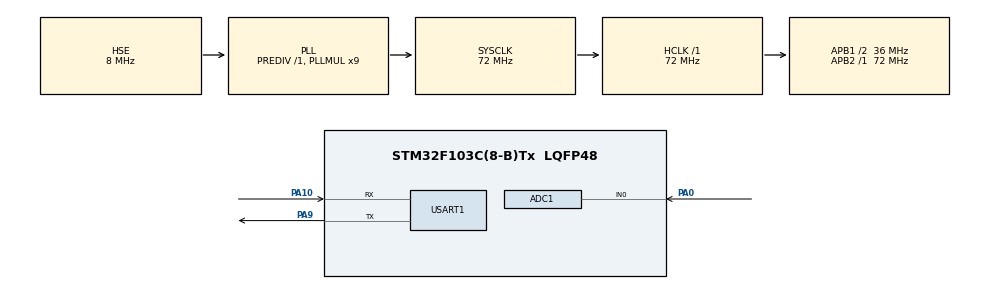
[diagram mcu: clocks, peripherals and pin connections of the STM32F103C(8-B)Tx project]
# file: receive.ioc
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ADC1.Channel-0\#ChannelRegularConversion=ADC_CHANNEL_0
ADC1.NbrOfConversionFlag=1
ADC1.Rank-0\#ChannelRegularConversion=1
ADC1.SamplingTime-0\#ChannelRegularConversion=ADC_SAMPLETIME_1CYCLE_5
ADC1.master=1
Dma.Request0=USART1_TX
Dma.Request1=USART1_RX
Dma.USART1_RX.1.Direction=DMA_PERIPH_TO_MEMORY
Dma.USART1_RX.1.Instance=DMA1_Channel5
Dma.USART1_RX.1.MemDataAlignment=DMA_MDATAALIGN_BYTE
Dma.USART1_RX.1.MemInc=DMA_MINC_ENABLE
Dma.USART1_RX.1.Mode=DMA_NORMAL
Dma.USART1_RX.1.PeriphDataAlignment=DMA_PDATAALIGN_BYTE
Dma.USART1_RX.1.PeriphInc=DMA_PINC_DISABLE
Dma.USART1_RX.1.Priority=DMA_PRIORITY_LOW
Dma.USART1_TX.0.Direction=DMA_MEMORY_TO_PERIPH
Dma.USART1_TX.0.Instance=DMA1_Channel4
Dma.USART1_TX.0.MemDataAlignment=DMA_MDATAALIGN_BYTE
Dma.USART1_TX.0.MemInc=DMA_MINC_ENABLE
Dma.USART1_TX.0.Mode=DMA_NORMAL
Dma.USART1_TX.0.PeriphDataAlignment=DMA_PDATAALIGN_BYTE
Dma.USART1_TX.0.PeriphInc=DMA_PINC_DISABLE
Dma.USART1_TX.0.Priority=DMA_PRIORITY_LOW
Mcu.Family=STM32F1
Mcu.Name=STM32F103C(8-B)Tx
Mcu.Package=LQFP48
NVIC.DMA1_Channel4_IRQn=true\:0\:0\:false\:false\:true\:false\:true\:true
NVIC.DMA1_Channel5_IRQn=true\:0\:0\:false\:false\:true\:false\:true\:true
NVIC.PriorityGroup=NVIC_PRIORITYGROUP_4
NVIC.USART1_IRQn=true\:0\:0\:false\:false\:true\:false\:true\:true
PA0-WKUP.Signal=ADCx_IN0
PA10.Mode=Asynchronous
PA10.Signal=USART1_RX
PA13.Mode=Serial_Wire
PA13.Signal=SYS_JTMS-SWDIO
PA14.Mode=Serial_Wire
PA14.Signal=SYS_JTCK-SWCLK
PA9.Mode=Asynchronous
PA9.Signal=USART1_TX
PD0-OSC_IN.Mode=HSE-External-Oscillator
PD0-OSC_IN.Signal=RCC_OSC_IN
PD1-OSC_OUT.Mode=HSE-External-Oscillator
PD1-OSC_OUT.Signal=RCC_OSC_OUT
ProjectManager.HeapSize=0x200
ProjectManager.StackSize=0x400
ProjectManager.TargetToolchain=CMake
RCC.ADCPresc=RCC_ADCPCLK2_DIV6
RCC.AHBFreq_Value=72000000
RCC.APB1CLKDivider=RCC_HCLK_DIV2
RCC.APB1Freq_Value=36000000
RCC.APB1TimFreq_Value=72000000
RCC.APB2Freq_Value=72000000
RCC.APB2TimFreq_Value=72000000
RCC.HCLKFreq_Value=72000000
RCC.PLLMUL=RCC_PLL_MUL9
RCC.PLLSourceVirtual=RCC_PLLSOURCE_HSE
RCC.SYSCLKFreq_VALUE=72000000
RCC.SYSCLKSource=RCC_SYSCLKSOURCE_PLLCLK
RCC.USBFreq_Value=72000000
SH.ADCx_IN0.0=ADC1_IN0,IN0
USART1.VirtualMode=VM_ASYNC
board=custom

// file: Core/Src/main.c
/* USER CODE BEGIN Header */
/**
  ******************************************************************************
  * @file           : main.c
  * @brief          : Main program body
  ******************************************************************************
  * @attention
  *
  * Copyright (c) 2026 STMicroelectronics.
  * All rights reserved.
  *
  * This software is licensed under terms that can be found in the LICENSE file
  * in the root directory of this software component.
  * If no LICENSE file comes with this software, it is provided AS-IS.
  *
  ******************************************************************************
  */
/* USER CODE END Header */
#include "main.h"

/* USER CODE BEGIN Includes */
#include <string.h>
/* USER CODE END Includes */

/* USER CODE BEGIN PD */
#define RX_BUF_SIZE   64U   /* DMA 接收缓冲区大小，一帧最长 64 字节 */
/* USER CODE END PD */

ADC_HandleTypeDef hadc1;

UART_HandleTypeDef huart1;
DMA_HandleTypeDef hdma_usart1_tx;
DMA_HandleTypeDef hdma_usart1_rx;

/* USER CODE BEGIN PV */
uint8_t           rx_buf[RX_BUF_SIZE];      /* DMA 直接写入的缓冲区 */
uint8_t           frame_buf[RX_BUF_SIZE];   /* 拷贝出来给主循环用，长度=实际收到字节数 */
volatile uint16_t frame_len   = 0U;         /* 本帧实际长度 */
volatile uint8_t  frame_ready = 0U;         /* 1 = 收到完整一帧，待主循环处理 */
/* USER CODE END PV */

void SystemClock_Config(void);
static void MX_GPIO_Init(void);
static void MX_DMA_Init(void);
static void MX_ADC1_Init(void);
static void MX_USART1_UART_Init(void);
/* USER CODE BEGIN PFP */
static void uart_send_str(const char *s);
static void uart_send_u16(uint16_t v);
static void uart_start_rx(void);
/* USER CODE END PFP */

/* USER CODE BEGIN 0 */
/* 发送一个以 '\0' 结尾的字符串 */
static void uart_send_str(const char *s)
{
  HAL_UART_Transmit(&huart1, (uint8_t *)s, (uint16_t)strlen(s), 100U);
}

/* 发送一个无符号整数（避免引入 printf，省 flash） */
static void uart_send_u16(uint16_t v)
{
  char    buf[6];
  uint8_t n = 0U;
  uint8_t i;
  char    t;

  if (v == 0U)
  {
    buf[n++] = '0';
  }
  else
  {
    while ((v > 0U) && (n < sizeof(buf)))
    {
      buf[n++] = (char)('0' + (v % 10U));
      v /= 10U;
    }
    for (i = 0U; i < (n / 2U); i++)      /* 上面是逆序，翻转回来 */
    {
      t = buf[i];
      buf[i] = buf[n - 1U - i];
      buf[n - 1U - i] = t;
    }
  }
  HAL_UART_Transmit(&huart1, (uint8_t *)buf, n, 100U);
}

/* 启动一次"不定长"接收：DMA 搬运 + 串口空闲中断判帧尾 */
static void uart_start_rx(void)
{
  HAL_UARTEx_ReceiveToIdle_DMA(&huart1, rx_buf, RX_BUF_SIZE);

  /* ReceiveToIdle_DMA 每次都会把 DMA 半传输中断也打开，
     缓冲区一半时会误触发一次回调。这里关掉，只要空闲事件。 */
  __HAL_DMA_DISABLE_IT(&hdma_usart1_rx, DMA_IT_HT);
}
/* USER CODE END 0 */

int main(void)
{

  /* MCU Configuration--------------------------------------------------------*/

  /* Reset of all peripherals, Initializes the Flash interface and the Systick. */
  HAL_Init();

  /* Configure the system clock */
  SystemClock_Config();

  /* Initialize all configured peripherals */
  MX_GPIO_Init();
  MX_DMA_Init();
  MX_ADC1_Init();
  MX_USART1_UART_Init();
  /* USER CODE BEGIN 2 */
  uart_send_str("\r\n===== 不定长数据接收（DMA + 空闲中断）=====\r\n");
  uart_send_str("发送任意长度内容，接收方会回显长度和原文\r\n");
  uart_send_str("缓冲区 ");
  uart_send_u16(RX_BUF_SIZE);
  uart_send_str(" 字节，超长会自动分帧\r\n");

  uart_start_rx();   /* 挂上第一次接收 */
  /* USER CODE END 2 */

  /* Infinite loop */
  while (1)
  {

    /* USER CODE BEGIN 3 */
    if (frame_ready != 0U)
    {
      uint16_t len;

      frame_ready = 0U;      /* 先清标志，再处理数据 */
      len = frame_len;

      /* 回显：长度 + 原文（发送长度本身就是"不定长发送"） */
      uart_send_str("\r\n[收到 ");
      uart_send_u16(len);
      uart_send_str(" 字节] ");
      if ((len > 0U) && (len <= RX_BUF_SIZE))
      {
        HAL_UART_Transmit(&huart1, frame_buf, len, 200U);
      }
      uart_send_str("\r\n");
    }
  }
  /* USER CODE END 3 */
}

void SystemClock_Config(void)
{
  RCC_OscInitTypeDef RCC_OscInitStruct = {0};
  RCC_ClkInitTypeDef RCC_ClkInitStruct = {0};
  RCC_PeriphCLKInitTypeDef PeriphClkInit = {0};

  /** Initializes the RCC Oscillators according to the specified parameters
  * in the RCC_OscInitTypeDef structure.
  */
  RCC_OscInitStruct.OscillatorType = RCC_OSCILLATORTYPE_HSE;
  RCC_OscInitStruct.HSEState = RCC_HSE_ON;
  RCC_OscInitStruct.HSEPredivValue = RCC_HSE_PREDIV_DIV1;
  RCC_OscInitStruct.HSIState = RCC_HSI_ON;
  RCC_OscInitStruct.PLL.PLLState = RCC_PLL_ON;
  RCC_OscInitStruct.PLL.PLLSource = RCC_PLLSOURCE_HSE;
  RCC_OscInitStruct.PLL.PLLMUL = RCC_PLL_MUL9;
  if (HAL_RCC_OscConfig(&RCC_OscInitStruct) != HAL_OK)
  {
    Error_Handler();
  }

  /** Initializes the CPU, AHB and APB buses clocks
  */
  RCC_ClkInitStruct.ClockType = RCC_CLOCKTYPE_HCLK|RCC_CLOCKTYPE_SYSCLK
                              |RCC_CLOCKTYPE_PCLK1|RCC_CLOCKTYPE_PCLK2;
  RCC_ClkInitStruct.SYSCLKSource = RCC_SYSCLKSOURCE_PLLCLK;
  RCC_ClkInitStruct.AHBCLKDivider = RCC_SYSCLK_DIV1;
  RCC_ClkInitStruct.APB1CLKDivider = RCC_HCLK_DIV2;
  RCC_ClkInitStruct.APB2CLKDivider = RCC_HCLK_DIV1;

  if (HAL_RCC_ClockConfig(&RCC_ClkInitStruct, FLASH_LATENCY_2) != HAL_OK)
  {
    Error_Handler();
  }
  PeriphClkInit.PeriphClockSelection = RCC_PERIPHCLK_ADC;
  PeriphClkInit.AdcClockSelection = RCC_ADCPCLK2_DIV6;
  if (HAL_RCCEx_PeriphCLKConfig(&PeriphClkInit) != HAL_OK)
  {
    Error_Handler();
  }
}

static void MX_ADC1_Init(void)
{

  ADC_ChannelConfTypeDef sConfig = {0};

  /** Common config
  */
  hadc1.Instance = ADC1;
  hadc1.Init.ScanConvMode = ADC_SCAN_DISABLE;
  hadc1.Init.ContinuousConvMode = DISABLE;
  hadc1.Init.DiscontinuousConvMode = DISABLE;
  hadc1.Init.ExternalTrigConv = ADC_SOFTWARE_START;
  hadc1.Init.DataAlign = ADC_DATAALIGN_RIGHT;
  hadc1.Init.NbrOfConversion = 1;
  if (HAL_ADC_Init(&hadc1) != HAL_OK)
  {
    Error_Handler();
  }

  /** Configure Regular Channel
  */
  sConfig.Channel = ADC_CHANNEL_0;
  sConfig.Rank = ADC_REGULAR_RANK_1;
  sConfig.SamplingTime = ADC_SAMPLETIME_1CYCLE_5;
  if (HAL_ADC_ConfigChannel(&hadc1, &sConfig) != HAL_OK)
  {
    Error_Handler();
  }

}

static void MX_USART1_UART_Init(void)
{

  huart1.Instance = USART1;
  huart1.Init.BaudRate = 115200;
  huart1.Init.WordLength = UART_WORDLENGTH_8B;
  huart1.Init.StopBits = UART_STOPBITS_1;
  huart1.Init.Parity = UART_PARITY_NONE;
  huart1.Init.Mode = UART_MODE_TX_RX;
  huart1.Init.HwFlowCtl = UART_HWCONTROL_NONE;
  huart1.Init.OverSampling = UART_OVERSAMPLING_16;
  if (HAL_UART_Init(&huart1) != HAL_OK)
  {
    Error_Handler();
  }

}

static void MX_DMA_Init(void)
{

  /* DMA controller clock enable */
  __HAL_RCC_DMA1_CLK_ENABLE();

  /* DMA interrupt init */
  /* DMA1_Channel4_IRQn interrupt configuration */
  HAL_NVIC_SetPriority(DMA1_Channel4_IRQn, 0, 0);
  HAL_NVIC_EnableIRQ(DMA1_Channel4_IRQn);
  /* DMA1_Channel5_IRQn interrupt configuration */
  HAL_NVIC_SetPriority(DMA1_Channel5_IRQn, 0, 0);
  HAL_NVIC_EnableIRQ(DMA1_Channel5_IRQn);

}

static void MX_GPIO_Init(void)
{

  /* GPIO Ports Clock Enable */
  __HAL_RCC_GPIOD_CLK_ENABLE();
  __HAL_RCC_GPIOA_CLK_ENABLE();

}

/* USER CODE BEGIN 4 */
/**
  * @brief  DMA 接收 + 空闲中断 的回调，Size = 本帧实际字节数
  * @note   进这里说明总线空闲了 3.5 个字节时间，一帧结束
  */
void HAL_UARTEx_RxEventCallback(UART_HandleTypeDef *huart, uint16_t Size)
{
  if (huart->Instance == USART1)
  {
    if (Size > RX_BUF_SIZE)
    {
      Size = RX_BUF_SIZE;
    }

    memcpy(frame_buf, rx_buf, Size);   /* 先搬走，DMA 缓冲区可立刻复用 */
    frame_len   = Size;
    frame_ready = 1U;

    uart_start_rx();                  /* 马上挂下一次接收，不丢数据 */
  }
}

/* 错误回调：溢出/噪声等异常时重新挂接收，否则串口会哑掉 */
void HAL_UART_ErrorCallback(UART_HandleTypeDef *huart)
{
  if (huart->Instance == USART1)
  {
    __HAL_UART_CLEAR_OREFLAG(&huart1);
    uart_start_rx();
  }
}
/* USER CODE END 4 */

void Error_Handler(void)
{
  __disable_irq();
  while (1)
  {
  }
}
